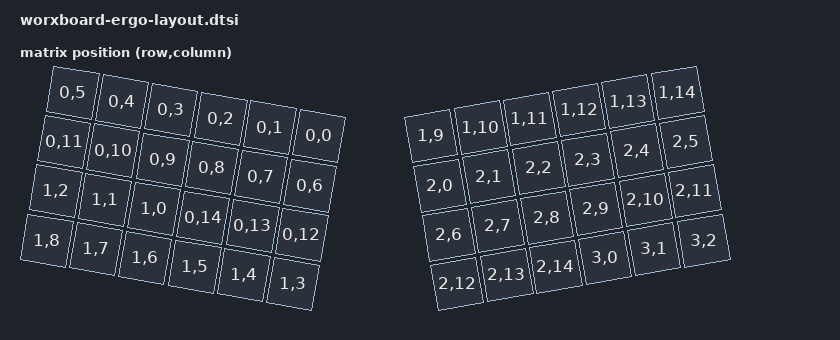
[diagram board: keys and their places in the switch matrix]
/* Generated by tools/firmware_layout.py. */
#include <physical_layouts.dtsi>
#include <dt-bindings/zmk/matrix_transform.h>
/ {
 ergo_transform: keymap_transform {
  compatible = "zmk,matrix-transform";
  rows = <4>; columns = <15>;
  map = <RC(0,0) RC(0,1) RC(0,2) RC(0,3) RC(0,4) RC(0,5) RC(0,6) RC(0,7) RC(0,8) RC(0,9) RC(0,10) RC(0,11) RC(0,12) RC(0,13) RC(0,14) RC(1,0) RC(1,1) RC(1,2) RC(1,3) RC(1,4) RC(1,5) RC(1,6) RC(1,7) RC(1,8) RC(1,9) RC(1,10) RC(1,11) RC(1,12) RC(1,13) RC(1,14) RC(2,0) RC(2,1) RC(2,2) RC(2,3) RC(2,4) RC(2,5) RC(2,6) RC(2,7) RC(2,8) RC(2,9) RC(2,10) RC(2,11) RC(2,12) RC(2,13) RC(2,14) RC(3,0) RC(3,1) RC(3,2)>;
 };
 ergo_layout: ergo_layout {
  compatible = "zmk,physical-layout";
  display-name = "Split Planck 48";
  transform = <&ergo_transform>;
  kscan = <&kscan0>;
  keys = <&key_physical_attrs 100 100 (-162) (-59) 1000 (-112) (-9)>, <&key_physical_attrs 100 100 (-261) (-76) 1000 (-211) (-26)>, <&key_physical_attrs 100 100 (-359) (-93) 1000 (-309) (-43)>, <&key_physical_attrs 100 100 (-458) (-111) 1000 (-408) (-61)>, <&key_physical_attrs 100 100 (-556) (-128) 1000 (-506) (-78)>, <&key_physical_attrs 100 100 (-655) (-146) 1000 (-605) (-96)>, <&key_physical_attrs 100 100 (-180) 40 1000 (-130) 90>, <&key_physical_attrs 100 100 (-278) 22 1000 (-228) 72>, <&key_physical_attrs 100 100 (-377) 5 1000 (-327) 55>, <&key_physical_attrs 100 100 (-475) (-12) 1000 (-425) 38>, <&key_physical_attrs 100 100 (-574) (-30) 1000 (-524) 20>, <&key_physical_attrs 100 100 (-672) (-47) 1000 (-622) 3>, <&key_physical_attrs 100 100 (-197) 138 1000 (-147) 188>, <&key_physical_attrs 100 100 (-295) 121 1000 (-245) 171>, <&key_physical_attrs 100 100 (-394) 104 1000 (-344) 154>, <&key_physical_attrs 100 100 (-492) 86 1000 (-442) 136>, <&key_physical_attrs 100 100 (-591) 69 1000 (-541) 119>, <&key_physical_attrs 100 100 (-689) 51 1000 (-639) 101>, <&key_physical_attrs 100 100 (-214) 237 1000 (-164) 287>, <&key_physical_attrs 100 100 (-313) 219 1000 (-263) 269>, <&key_physical_attrs 100 100 (-411) 202 1000 (-361) 252>, <&key_physical_attrs 100 100 (-510) 185 1000 (-460) 235>, <&key_physical_attrs 100 100 (-608) 167 1000 (-558) 217>, <&key_physical_attrs 100 100 (-707) 150 1000 (-657) 200>, <&key_physical_attrs 100 100 62 (-59) (-1000) 112 (-9)>, <&key_physical_attrs 100 100 161 (-76) (-1000) 211 (-26)>, <&key_physical_attrs 100 100 259 (-93) (-1000) 309 (-43)>, <&key_physical_attrs 100 100 358 (-111) (-1000) 408 (-61)>, <&key_physical_attrs 100 100 456 (-128) (-1000) 506 (-78)>, <&key_physical_attrs 100 100 555 (-146) (-1000) 605 (-96)>, <&key_physical_attrs 100 100 80 40 (-1000) 130 90>, <&key_physical_attrs 100 100 178 22 (-1000) 228 72>, <&key_physical_attrs 100 100 277 5 (-1000) 327 55>, <&key_physical_attrs 100 100 375 (-12) (-1000) 425 38>, <&key_physical_attrs 100 100 474 (-30) (-1000) 524 20>, <&key_physical_attrs 100 100 572 (-47) (-1000) 622 3>, <&key_physical_attrs 100 100 97 138 (-1000) 147 188>, <&key_physical_attrs 100 100 195 121 (-1000) 245 171>, <&key_physical_attrs 100 100 294 104 (-1000) 344 154>, <&key_physical_attrs 100 100 392 86 (-1000) 442 136>, <&key_physical_attrs 100 100 491 69 (-1000) 541 119>, <&key_physical_attrs 100 100 589 51 (-1000) 639 101>, <&key_physical_attrs 100 100 114 237 (-1000) 164 287>, <&key_physical_attrs 100 100 213 219 (-1000) 263 269>, <&key_physical_attrs 100 100 311 202 (-1000) 361 252>, <&key_physical_attrs 100 100 410 185 (-1000) 460 235>, <&key_physical_attrs 100 100 508 167 (-1000) 558 217>, <&key_physical_attrs 100 100 607 150 (-1000) 657 200>;
 };
};
